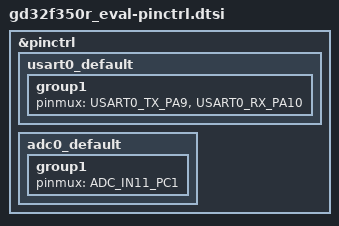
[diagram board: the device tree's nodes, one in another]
/*
 * Copyright (c) 2021 BrainCo Inc.
 * SPDX-License-Identifier: Apache-2.0
 */

#include <dt-bindings/pinctrl/gd32f350r(8-b)xx-pinctrl.h>

&pinctrl {
	usart0_default: usart0_default {
		group1 {
			pinmux = <USART0_TX_PA9>, <USART0_RX_PA10>;
		};
	};

	adc0_default: adc0_default {
		group1 {
			pinmux = <ADC_IN11_PC1>;
		};
	};
};
